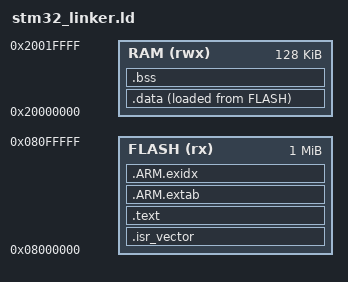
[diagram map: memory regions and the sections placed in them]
/**
 * @file stm32_linker.ld
 * @brief Linker script for STM32 microcontroller
 * @details Generic linker script for STM32F4 series
 *          Adjust FLASH and RAM sizes for your specific MCU
 */

/* Memory layout for STM32F4 (example: STM32F407VG) */
MEMORY
{
    FLASH (rx)  : ORIGIN = 0x08000000, LENGTH = 1024K
    RAM (rwx)   : ORIGIN = 0x20000000, LENGTH = 128K
}

/* Entry point */
ENTRY(Reset_Handler)

/* Stack size */
_estack = ORIGIN(RAM) + LENGTH(RAM);

SECTIONS
{
    /* Vector table */
    .isr_vector :
    {
        . = ALIGN(4);
        KEEP(*(.isr_vector))
        . = ALIGN(4);
    } > FLASH

    /* Program code */
    .text :
    {
        . = ALIGN(4);
        *(.text)
        *(.text*)
        *(.rodata)
        *(.rodata*)
        *(.glue_7)
        *(.glue_7t)
        . = ALIGN(4);
        _etext = .;
    } > FLASH

    /* ARM exception unwinding */
    .ARM.extab :
    {
        *(.ARM.extab*)
    } > FLASH

    .ARM.exidx :
    {
        __exidx_start = .;
        *(.ARM.exidx*)
        __exidx_end = .;
    } > FLASH

    /* Initialized data */
    _sidata = LOADADDR(.data);
    .data :
    {
        . = ALIGN(4);
        _sdata = .;
        *(.data)
        *(.data*)
        . = ALIGN(4);
        _edata = .;
    } > RAM AT> FLASH

    /* Uninitialized data */
    .bss :
    {
        . = ALIGN(4);
        _sbss = .;
        *(.bss)
        *(.bss*)
        *(COMMON)
        . = ALIGN(4);
        _ebss = .;
    } > RAM
}
